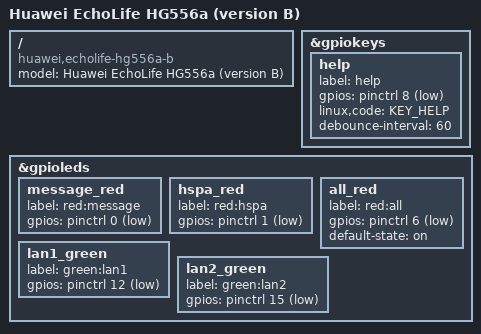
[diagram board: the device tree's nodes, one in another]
#include "bcm6358-huawei-echolife-hg556a.dtsi"

/ {
	model = "Huawei EchoLife HG556a (version B)";
	compatible = "huawei,echolife-hg556a-b", "brcm,bcm6358";
};

&gpiokeys {
	help {
		label = "help";
		gpios = <&pinctrl 8 1>;
		linux,code = <KEY_HELP>;
		debounce-interval = <60>;
	};
};

&gpioleds {
	message_red {
		label = "red:message";
		gpios = <&pinctrl 0 1>;
	};

	hspa_red {
		label = "red:hspa";
		gpios = <&pinctrl 1 1>;
	};

	all_red {
		label = "red:all";
		gpios = <&pinctrl 6 1>;
		default-state = "on";
	};

	lan1_green {
		label = "green:lan1";
		gpios = <&pinctrl 12 1>;
	};

	lan2_green {
		label = "green:lan2";
		gpios = <&pinctrl 15 1>;
	};
};
